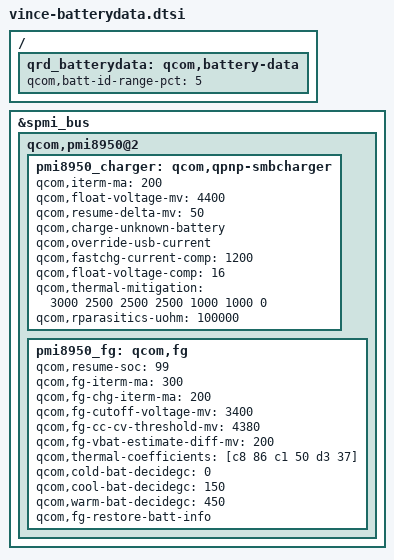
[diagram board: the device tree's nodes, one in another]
/* Copyright (c) 2017, The Linux Foundation. All rights reserved.
 *
 * This program is free software; you can redistribute it and/or modify
 * it under the terms of the GNU General Public License version 2 and
 * only version 2 as published by the Free Software Foundation.
 *
 * This program is distributed in the hope that it will be useful,
 * but WITHOUT ANY WARRANTY; without even the implied warranty of
 * MERCHANTABILITY or FITNESS FOR A PARTICULAR PURPOSE.  See the
 * GNU General Public License for more details.
 */

/ {
	qrd_batterydata: qcom,battery-data {
		qcom,batt-id-range-pct = <5>;
		#include "Vince-sunwoda-40Kohm-4000mah.dtsi"
		#include "Vince-desay-24Kohm-4000mAh.dtsi"
		#include "Vince-coslight-50Kohm-4000mah.dtsi"
		/delete-node/ qcom,qrd_msm8937_sku1_2920mah;
	};
};

&spmi_bus {
	qcom,pmi8950@2 {
		pmi8950_charger: qcom,qpnp-smbcharger {
			qcom,iterm-ma = <200>; 
			qcom,float-voltage-mv = <4400>;
			qcom,resume-delta-mv = <50>;
			qcom,charge-unknown-battery;
			qcom,override-usb-current;
			qcom,fastchg-current-comp = <1200>;
			qcom,float-voltage-comp = <16>;
			qcom,thermal-mitigation = <3000 2500 2500 2500 1000 1000 0>;
			qcom,rparasitics-uohm = <100000>;
			/delete-property/ qcom,parallel-usb-min-current-ma;
			/delete-property/ qcom,parallel-usb-9v-min-current-ma;
			/delete-property/ qcom,parallel-allowed-lowering-ma;
			/delete-property/ qcom,chg-led-sw-controls;
			/delete-property/ qcom,chg-led-support;
			/delete-property/ qcom,external-typec;
			/delete-property/ qcom,typec-psy-name;
			/delete-property/ qcom,autoadjust-vfloat;
			/delete-property/ qcom,rparasitic-uohm;
		};

     		pmi8950_fg: qcom,fg {
        	        qcom,resume-soc = <99>;
 			qcom,fg-iterm-ma = <300>;
			qcom,fg-chg-iterm-ma = <200>; 
			qcom,fg-cutoff-voltage-mv = <3400>;
			qcom,fg-cc-cv-threshold-mv = <4380>;
			qcom,fg-vbat-estimate-diff-mv = <200>;
			qcom,thermal-coefficients = [c8 86 c1 50 d3 37];
			qcom,cold-bat-decidegc = <0>;
			qcom,cool-bat-decidegc = <150>;
			qcom,warm-bat-decidegc = <450>;
			qcom,fg-restore-batt-info;
		};
	};
};
